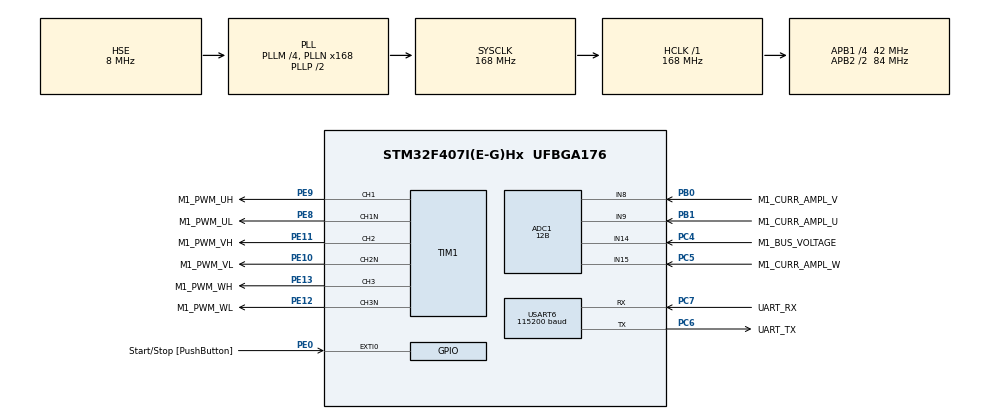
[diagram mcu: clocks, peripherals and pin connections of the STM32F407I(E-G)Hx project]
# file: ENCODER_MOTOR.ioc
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ADC1.Channel-1\#ChannelInjectedConversion=ADC_CHANNEL_9
ADC1.Channel-1\#ChannelRegularConversion=ADC_CHANNEL_14
ADC1.Channel-2\#ChannelInjectedConversion=ADC_CHANNEL_8
ADC1.Channel-3\#ChannelInjectedConversion=ADC_CHANNEL_15
ADC1.ClockPrescaler=ADC_CLOCK_SYNC_PCLK_DIV4
ADC1.ContinuousConvMode=DISABLE
ADC1.DMAContinuousRequests=DISABLE
ADC1.DataAlign=ADC_DATAALIGN_LEFT
ADC1.DiscontinuousConvMode=DISABLE
ADC1.EOCSelection=ADC_EOC_SINGLE_CONV
ADC1.EnableAnalogWatchDog=false
ADC1.EnableInjectedConversion=ENABLE
ADC1.EnableRegularConversion=ENABLE
ADC1.ExternalTrigConv=ADC_SOFTWARE_START
ADC1.ExternalTrigConvEdge=ADC_EXTERNALTRIGCONVEDGE_NONE
ADC1.ExternalTrigInjecConv=ADC_EXTERNALTRIGINJECCONV_T1_CC4
ADC1.ExternalTrigInjecConvEdge=ADC_EXTERNALTRIGINJECCONVEDGE_RISING
ADC1.InjNumberOfConversion=3
ADC1.InjectedConvMode=Discontinuous
ADC1.InjectedOffset-1\#ChannelInjectedConversion=0
ADC1.InjectedOffset-2\#ChannelInjectedConversion=0
ADC1.InjectedOffset-3\#ChannelInjectedConversion=0
ADC1.InjectedRank-1\#ChannelInjectedConversion=1
ADC1.InjectedRank-2\#ChannelInjectedConversion=2
ADC1.InjectedRank-3\#ChannelInjectedConversion=3
ADC1.NbrOfConversion=1
ADC1.NbrOfConversionFlag=1
ADC1.Offset-1\#ChannelRegularConversion=0
ADC1.OffsetNumber-1\#ChannelRegularConversion=ADC_OFFSET_NONE
ADC1.Rank-1\#ChannelRegularConversion=1
ADC1.Resolution=ADC_RESOLUTION_12B
ADC1.SamplingTime-1\#ChannelInjectedConversion=ADC_SAMPLETIME_3CYCLES
ADC1.SamplingTime-1\#ChannelRegularConversion=ADC_SAMPLETIME_56CYCLES
ADC1.SamplingTime-2\#ChannelInjectedConversion=ADC_SAMPLETIME_3CYCLES
ADC1.SamplingTime-3\#ChannelInjectedConversion=ADC_SAMPLETIME_3CYCLES
ADC1.ScanConvMode=ENABLE
ADC1.master=1
ADC2.Channel-1\#ChannelInjectedConversion=ADC_CHANNEL_9
ADC2.Channel-1\#ChannelRegularConversion=ADC_CHANNEL_9
ADC2.Channel-2\#ChannelInjectedConversion=ADC_CHANNEL_8
ADC2.Channel-3\#ChannelInjectedConversion=ADC_CHANNEL_15
ADC2.ClockPrescaler=ADC_CLOCK_SYNC_PCLK_DIV4
ADC2.ContinuousConvMode=DISABLE
ADC2.DMAContinuousRequests=DISABLE
ADC2.DataAlign=ADC_DATAALIGN_LEFT
ADC2.DiscontinuousConvMode=DISABLE
ADC2.EOCSelection=ADC_EOC_SINGLE_CONV
ADC2.EnableAnalogWatchDog=false
ADC2.EnableInjectedConversion=ENABLE
ADC2.EnableRegularConversion=ENABLE
ADC2.ExternalTrigConv=ADC_SOFTWARE_START
ADC2.ExternalTrigConvEdge=ADC_EXTERNALTRIGCONVEDGE_NONE
ADC2.ExternalTrigInjecConv=ADC_EXTERNALTRIGINJECCONV_T1_CC4
ADC2.ExternalTrigInjecConvEdge=ADC_EXTERNALTRIGINJECCONVEDGE_RISING
ADC2.InjNumberOfConversion=3
ADC2.InjectedConvMode=Discontinuous
ADC2.InjectedOffset-1\#ChannelInjectedConversion=0
ADC2.InjectedOffset-2\#ChannelInjectedConversion=0
ADC2.InjectedOffset-3\#ChannelInjectedConversion=0
ADC2.InjectedRank-1\#ChannelInjectedConversion=1
ADC2.InjectedRank-2\#ChannelInjectedConversion=2
ADC2.InjectedRank-3\#ChannelInjectedConversion=3
ADC2.NbrOfConversion=1
ADC2.NbrOfConversionFlag=1
ADC2.Rank-1\#ChannelRegularConversion=1
ADC2.Resolution=ADC_RESOLUTION_12B
ADC2.SamplingTime-1\#ChannelInjectedConversion=ADC_SAMPLETIME_3CYCLES
ADC2.SamplingTime-1\#ChannelRegularConversion=ADC_SAMPLETIME_3CYCLES
ADC2.SamplingTime-2\#ChannelInjectedConversion=ADC_SAMPLETIME_3CYCLES
ADC2.SamplingTime-3\#ChannelInjectedConversion=ADC_SAMPLETIME_3CYCLES
ADC2.ScanConvMode=ENABLE
ExtraMW=MotorControl
ExtraMW.MotorControl.Config=MotorControl
ExtraMW.MotorControl.Mode=MotorControl
ExtraMW.MotorControl.Root=MCSDK_v5.4.8/MotorControl
ExtraMW.MotorControl.Template=templates
Mcu.Family=STM32F4
Mcu.Name=STM32F407I(E-G)Hx
Mcu.Package=UFBGA176
MotorControl.ADC_1_PERIPH=ADC1
MotorControl.ADC_2_PERIPH=ADC2
MotorControl.ADC_AHBPERIPH=RCC_AHBPeriph_ADC12
MotorControl.ADC_CLOCK_WB_DIV=1
MotorControl.ADC_CLOCK_WB_FREQ=21
MotorControl.ADC_PERIPH=ADC1
MotorControl.ADC_REFERENCE_VOLTAGE=3.30
MotorControl.ALIGNMENT_ANGLE_DEG=90
MotorControl.ALIGNMENT_DURATION=700
MotorControl.AMPLIFICATION_GAIN=20.00
MotorControl.ANGC={0,0,0,0,0,0,0,0}
MotorControl.AUXILIARY_SPEED_MEASUREMENT_SELECTION=AUX_STATE_OBSERVER_CORDIC
MotorControl.AUX_STATE_OBSERVER_CORDIC=true
MotorControl.BEMF_CONSISTENCY_GAIN=64
MotorControl.BEMF_CONSISTENCY_TOL=64
MotorControl.BKIN1_FILTER=0
MotorControl.BKIN2_FILTER=0
MotorControl.BKIN2_MODE=NONE
MotorControl.BKIN_MODE=NONE
MotorControl.BOARD=CUSTOM
MotorControl.BRKIN2_GPIO_AF=GPIO_AF_2
MotorControl.BRKIN_GPIO_AF=GPIO_AF_2
MotorControl.BUS_VOLTAGE_READING=true
MotorControl.CCMRAM_ENABLED=false
MotorControl.CLOCK_FREQUENCY=CPU_CLK_168_MHZ
MotorControl.CLOCK_SOURCE=EXTERNAL
MotorControl.CONSTANT1_D=147062
MotorControl.CONSTANT1_Q=147062
MotorControl.CONSTANT2_QD=28666
MotorControl.CORD_BEMF_CONSISTENCY_GAIN=64
MotorControl.CORD_BEMF_CONSISTENCY_TOL=64
MotorControl.CORD_F1=16384
MotorControl.CORD_F2=16384
MotorControl.CORD_FIFO_DEPTH_01HZ=64
MotorControl.CORD_FIFO_DEPTH_DPP=64
MotorControl.CORD_GAIN1=-20932
MotorControl.CORD_GAIN2=20828
MotorControl.CORD_MAX_ACCEL_DPPP=26
MotorControl.CORD_MEAS_ERRORS_BEFORE_FAULTS=50
MotorControl.CORD_VARIANCE_THRESHOLD=4
MotorControl.CPU_CLK_168_MHZ=true
MotorControl.CTRBDID=0
MotorControl.CUBE_MX_VER=6.7.0
MotorControl.CURRENT_READING_TOPOLOGY=THREE_SHUNT_INDEPENDENT_RESOURCES
MotorControl.CURR_SAMPLING_TIME=3
MotorControl.DAC_EMULATED=false
MotorControl.DAC_FUNCTIONALITY=false
MotorControl.DAC_TIMER_CH1_GPIO_PIN=LL_GPIO_PIN_0
MotorControl.DAC_TIMER_CH1_GPIO_PORT=GPIOA
MotorControl.DAC_TIMER_CH2_GPIO_PIN=LL_GPIO_PIN_0
MotorControl.DAC_TIMER_CH2_GPIO_PORT=GPIOA
MotorControl.DAC_TIMER_SELECTION=TIM3
MotorControl.DC_CURRENT_RS_MEAS=13.85
MotorControl.DEBUG_DAC_CH1=false
MotorControl.DEBUG_DAC_CH2=false
MotorControl.DEFAULT_CONTROL_MODE=STC_SPEED_MODE
MotorControl.DEFAULT_DAC_CHANNEL_1=MC_PROTOCOL_REG_I_A
MotorControl.DEFAULT_DAC_CHANNEL_2=MC_PROTOCOL_REG_I_B
MotorControl.DEFAULT_DAC_MOTOR=0
MotorControl.DEFAULT_FLUX_COMPONENT=0
MotorControl.DEFAULT_TARGET_SPEED_RPM=1000
MotorControl.DEFAULT_TORQUE_COMPONENT=0
MotorControl.DISSIPATIVE_BRAKE_POLARITY=DOUT_ACTIVE_HIGH
MotorControl.DRIVES_NUMBER_SELECTION=SINGLEDRIVE
MotorControl.EMERGENCY2_STOP_GPIO_PIN=LL_GPIO_PIN_6
MotorControl.EMERGENCY2_STOP_GPIO_PORT=GPIOA
MotorControl.EMERGENCY_STOP_GPIO_PIN=LL_GPIO_PIN_6
MotorControl.EMERGENCY_STOP_GPIO_PORT=GPIOA
MotorControl.ENABLE_SL_ALGO_FROM_PHASE=1
MotorControl.ENCODER_AVAILABLE=false
MotorControl.ENCODER_PPR=1000
MotorControl.ENC_AVERAGING_FIFO_DEPTH=16
MotorControl.ENC_A_GPIO_PIN=LL_GPIO_PIN_4
MotorControl.ENC_A_GPIO_PORT=GPIOB
MotorControl.ENC_B_GPIO_PIN=LL_GPIO_PIN_5
MotorControl.ENC_B_GPIO_PORT=GPIOB
MotorControl.ENC_ICx_FILTER=64
MotorControl.ENC_INVERT_SPEED=false
MotorControl.ENC_MEAS_ERRORS_BEFORE_FAULTS=50
MotorControl.ENC_TIMER_REMAPPING=NO_REMAP_TIM3
MotorControl.ENC_TIMER_SELECTION=ENC_TIM3
MotorControl.ENC_USE_CH3=false
MotorControl.EXT_CLK_8_MHZ=true
MotorControl.EXT_CLOCK_FREQUENCY=EXT_CLK_8_MHZ
MotorControl.F1=16384
MotorControl.F2=4096
MotorControl.FEEDBACK_NET_FILTERING=false
MotorControl.FEED_FORWARD_CURRENT_REG_ENABLING=false
MotorControl.FINAL_I_ALIGNMENT=2383
MotorControl.FLUX_WEAKENING_ENABLING=false
MotorControl.FW_KIDIV=32768
MotorControl.FW_KI_GAIN=5000
MotorControl.FW_KPDIV=32768
MotorControl.FW_KP_GAIN=3000
MotorControl.FW_VOLTAGE_REF=985
MotorControl.GAIN1=-23932
MotorControl.GAIN2=20828
MotorControl.H1_GPIO_PIN=LL_GPIO_PIN_10
MotorControl.H1_GPIO_PORT=GPIOH
MotorControl.H2_GPIO_PIN=LL_GPIO_PIN_11
MotorControl.H2_GPIO_PORT=GPIOH
MotorControl.H3_GPIO_PIN=LL_GPIO_PIN_12
MotorControl.H3_GPIO_PORT=GPIOH
MotorControl.HALL_AVERAGING_FIFO_DEPTH=6
MotorControl.HALL_ICx_FILTER=96
MotorControl.HALL_MEAS_ERRORS_BEFORE_FAULTS=50
MotorControl.HALL_MTPA=false
MotorControl.HALL_PHASE_SHIFT=120
MotorControl.HALL_SENSORS_AVAILABLE=false
MotorControl.HALL_SENSORS_PLACEMENT=DEGREES_120
MotorControl.HALL_TIMER_REMAPPING=NO_REMAP_TIM5
MotorControl.HALL_TIMER_SELECTION=HALL_TIM5
MotorControl.HFI_AMPLITUDE=25
MotorControl.HFI_DC_0_COEFF=0.00146
MotorControl.HFI_DC_1_COEFF=0.002921
MotorControl.HFI_DC_2_COEFF=0.00146
MotorControl.HFI_DC_3_COEFF=1.889033
MotorControl.HFI_DC_4_COEFF=-0.894874
MotorControl.HFI_DEBUG_MODE=false
MotorControl.HFI_FREQUENCY=400
MotorControl.HFI_HIFRAMPLSCAN=25
MotorControl.HFI_HP_ID_0_COEFF=0.939693
MotorControl.HFI_HP_ID_1_COEFF=-1.879386
MotorControl.HFI_HP_ID_2_COEFF=0.939693
MotorControl.HFI_HP_ID_3_COEFF=1.875746
MotorControl.HFI_HP_ID_4_COEFF=-0.883026
MotorControl.HFI_IDH_DELAY=32400
MotorControl.HFI_LOCKFREQ=33
MotorControl.HFI_LP_ID_0_COEFF=0.00597
MotorControl.HFI_LP_ID_1_COEFF=0.011941
MotorControl.HFI_LP_ID_2_COEFF=0.00597
MotorControl.HFI_LP_ID_3_COEFF=1.769837
MotorControl.HFI_LP_ID_4_COEFF=-0.793719
MotorControl.HFI_MAXANGLEDIFF=3640
MotorControl.HFI_MINIMUM_SPEED_RPM=402
MotorControl.HFI_NOTCH_IQD_0_COEFF=0.969619
MotorControl.HFI_NOTCH_IQD_1_COEFF=-1.923946
MotorControl.HFI_NOTCH_IQD_2_COEFF=0.969619
MotorControl.HFI_NOTCH_IQD_3_COEFF=1.923946
MotorControl.HFI_NOTCH_IQD_4_COEFF=-0.939237
MotorControl.HFI_NSDETPOINTSSKIP=10
MotorControl.HFI_NSMAXDETPOINTS=20
MotorControl.HFI_NS_MIN_SAT_DIFF=0
MotorControl.HFI_PID_KIDIV=32768
MotorControl.HFI_PID_KI_DEFAULT=400
MotorControl.HFI_PID_KPDIV=16384
MotorControl.HFI_PID_KP_DEFAULT=800
MotorControl.HFI_PLL_KI_DEFAULT=0.00400
MotorControl.HFI_PLL_KP_DEFAULT=0.00060
MotorControl.HFI_RESTARTTIMESEC=0.1
MotorControl.HFI_RESTART_RPM_TH=(((HFI_STO_RPM_TH)+(STO_HFI_RPM_TH))/2)
MotorControl.HFI_REVERT_DIRECTION=true
MotorControl.HFI_SCANROTATIONSNO=3
MotorControl.HFI_SPD_BUFFER_DEPTH_01HZ=64
MotorControl.HFI_STEPANGLE=3640
MotorControl.HFI_STO_RPM_TH=OBS_MINIMUM_SPEED_RPM
MotorControl.HFI_WAITAFTERNS2=4
MotorControl.HFI_WAITBEFORESN=6
MotorControl.HFI_WAITSYNCH=20
MotorControl.HFI_WAITTRACK=20
MotorControl.HIGH_SIDE_BRAKE_STATE=false
MotorControl.HIGH_SIDE_IDLE_STATE=false
MotorControl.HW_COMPLEMENTED_LOW_SIDE=false
MotorControl.HW_DEAD_TIME_NS=100
MotorControl.HW_OV_CURRENT_PROT_BYPASS=false
MotorControl.ID_DEMAG=-16502
MotorControl.INRUSH_CURRLIMIT_AT_POWER_ON=true
MotorControl.INRUSH_CURRLIMIT_CHANGE_AFTER_MS=1000
MotorControl.INRUSH_CURRLIMIT_ENABLING=false
MotorControl.INRUSH_CURRLIMIT_GPIO_PIN=LL_GPIO_PIN_4
MotorControl.INRUSH_CURRLIMIT_GPIO_PORT=GPIOE
MotorControl.INRUSH_CURR_LIMITER_POLARITY=DOUT_ACTIVE_HIGH
MotorControl.INTERNAL_OVERCURRENTPROTECTION=false
MotorControl.INTERNAL_OVERVOLTAGEPROTECTION=false
MotorControl.IPs=NVIC,RCC,SYS,MotorControl,ADC1,ADC2,TIM1,USART6
MotorControl.IQMAX=16502
MotorControl.LCD_JOYSTICK_FUNCTIONALITY=false
MotorControl.LCD_MODE=LCD_FULL
MotorControl.LDLQ_RATIO=1.000
MotorControl.LOW_SIDE_BRAKE_STATE=false
MotorControl.LOW_SIDE_IDLE_STATE=false
MotorControl.LOW_SIDE_SIGNALS_ENABLING=LS_PWM_TIMER
MotorControl.LS=0.000200
MotorControl.MAX_APPLICATION_SPEED=5500
MotorControl.MAX_MODULATION_89_PER_CENT=true
MotorControl.MAX_MODULATION_INDEX=MAX_MODULATION_89_PER_CENT
MotorControl.MCU=STM32F407IG
MotorControl.MCU_TYPE=STM32F4xx
MotorControl.MC_WORKBENCH_VERSION=5.4.8.21553
MotorControl.MEAS_ERRORS_BEFORE_FAULTS=50
MotorControl.MIN_APPLICATION_SPEED=0
MotorControl.MOTOR_MAX_SPEED_RPM=5500
MotorControl.MOTOR_TYPE=PMSM
MotorControl.MOTOR_VOLTAGE_CONSTANT=4.4
MotorControl.MTPA_ENABLING=false
MotorControl.NB_CONSECUTIVE_TESTS=1
MotorControl.NOMINAL_BUS_VOLTAGE_V=24
MotorControl.NOMINAL_CURRENT=16502
MotorControl.OBS_MEAS_ERRORS_BEFORE_FAULTS=50
MotorControl.OBS_MINIMUM_SPEED_RPM=700
MotorControl.OCPA_INVERTINGINPUT=COMPX_InvertingInput_VREF
MotorControl.OCPA_INVERTINGINPUT_GPIO_PIN=LL_GPIO_PIN_4
MotorControl.OCPA_INVERTINGINPUT_GPIO_PORT=GPIOA
MotorControl.OCPA_INVERTINGINPUT_MODE=INT_MODE
MotorControl.OCPA_NONINVERTINGINPUT=COMP1_NonInvertingInput_PA1
MotorControl.OCPA_NONINVERTINGINPUT_GPIO_PIN=LL_GPIO_PIN_1
MotorControl.OCPA_NONINVERTINGINPUT_GPIO_PORT=GPIOA
MotorControl.OCPA_OUTPUT=COMP_Output_TIM1BKIN2
MotorControl.OCPA_OUTPUTPOL=COMP_OutputPol_NonInverted
MotorControl.OCPA_OUTPUT_GPIO_AF=GPIO_AF_8
MotorControl.OCPA_OUTPUT_GPIO_PIN=LL_GPIO_PIN_0
MotorControl.OCPA_OUTPUT_GPIO_PORT=GPIOA
MotorControl.OCPA_OUTPUT_MODE=INT_MODE
MotorControl.OCPA_SELECTION=COMP1
MotorControl.OCPB_INVERTINGINPUT=COMPX_InvertingInput_VREF
MotorControl.OCPB_INVERTINGINPUT_GPIO_PIN=LL_GPIO_PIN_4
MotorControl.OCPB_INVERTINGINPUT_GPIO_PORT=GPIOA
MotorControl.OCPB_INVERTINGINPUT_MODE=INT_MODE
MotorControl.OCPB_NONINVERTINGINPUT=COMP2_NonInvertingInput_PA7
MotorControl.OCPB_NONINVERTINGINPUT_GPIO_PIN=LL_GPIO_PIN_7
MotorControl.OCPB_NONINVERTINGINPUT_GPIO_PORT=GPIOA
MotorControl.OCPB_OUTPUT=COMP_Output_TIM1BKIN2
MotorControl.OCPB_OUTPUTPOL=COMP_OutputPol_NonInverted
MotorControl.OCPB_OUTPUT_GPIO_AF=GPIO_AF_8
MotorControl.OCPB_OUTPUT_GPIO_PIN=LL_GPIO_PIN_2
MotorControl.OCPB_OUTPUT_GPIO_PORT=GPIOA
MotorControl.OCPB_OUTPUT_MODE=INT_MODE
MotorControl.OCPB_SELECTION=COMP2
MotorControl.OCPC_INVERTINGINPUT=COMPX_InvertingInput_VREF
MotorControl.OCPC_INVERTINGINPUT_GPIO_PIN=LL_GPIO_PIN_4
MotorControl.OCPC_INVERTINGINPUT_GPIO_PORT=GPIOA
MotorControl.OCPC_INVERTINGINPUT_MODE=INT_MODE
MotorControl.OCPC_NONINVERTINGINPUT=COMP3_NonInvertingInput_PD14
MotorControl.OCPC_NONINVERTINGINPUT_GPIO_PIN=LL_GPIO_PIN_14
MotorControl.OCPC_NONINVERTINGINPUT_GPIO_PORT=GPIOD
MotorControl.OCPC_OUTPUT=COMP_Output_TIM1BKIN2
MotorControl.OCPC_OUTPUTPOL=COMP_OutputPol_NonInverted
MotorControl.OCPC_OUTPUT_GPIO_AF=GPIO_AF_7
MotorControl.OCPC_OUTPUT_GPIO_PIN=LL_GPIO_PIN_8
MotorControl.OCPC_OUTPUT_GPIO_PORT=GPIOC
MotorControl.OCPC_OUTPUT_MODE=INT_MODE
MotorControl.OCPC_SELECTION=COMP3
MotorControl.OCPREF=23830
MotorControl.OCP_COMP_THRESHOLD=0.50
MotorControl.OCP_FILTER=COMP_Mode_HighSpeed
MotorControl.OCP_INVERTINGINPUT=COMPX_InvertingInput_VREF
MotorControl.OCP_INVERTINGINPUT_GPIO_PIN=LL_GPIO_PIN_4
MotorControl.OCP_INVERTINGINPUT_GPIO_PORT=GPIOA
MotorControl.OCP_INVERTINGINPUT_MODE=INT_MODE
MotorControl.OCP_NONINVERTINGINPUT=COMP2_NonInvertingInput_PA7
MotorControl.OCP_NONINVERTINGINPUT_GPIO_PIN=LL_GPIO_PIN_7
MotorControl.OCP_NONINVERTINGINPUT_GPIO_PORT=GPIOA
MotorControl.OCP_OUTPUT=COMP_Output_TIM1BKIN2
MotorControl.OCP_OUTPUTPOL=COMP_OutputPol_NonInverted
MotorControl.OCP_OUTPUT_GPIO_AF=GPIO_AF_8
MotorControl.OCP_OUTPUT_GPIO_PIN=LL_GPIO_PIN_2
MotorControl.OCP_OUTPUT_GPIO_PORT=GPIOA
MotorControl.OCP_OUTPUT_MODE=INT_MODE
MotorControl.OCP_SELECTION=COMP2
MotorControl.OFST={0,0,0,0,0,0,0,0}
MotorControl.ON_OVER_VOLTAGE=TURN_OFF_PWM
MotorControl.OPAMP1_INVERTINGINPUT=OPAMP1_InvertingInput_PGA
MotorControl.OPAMP1_INVERTINGINPUT_GPIO_PIN=LL_GPIO_PIN_3
MotorControl.OPAMP1_INVERTINGINPUT_GPIO_PORT=GPIOA
MotorControl.OPAMP1_INVERTINGINPUT_MODE=INT_MODE
MotorControl.OPAMP1_NONINVERTINGINPUT_PHA=OPAMP1_NonInvertingInput_PA1
MotorControl.OPAMP1_NONINVERTINGINPUT_PHA_GPIO_PIN=LL_GPIO_PIN_1
MotorControl.OPAMP1_NONINVERTINGINPUT_PHA_GPIO_PORT=GPIOA
MotorControl.OPAMP1_NONINVERTINGINPUT_PHB=OPAMP1_NonInvertingInput_PA7
MotorControl.OPAMP1_NONINVERTINGINPUT_PHB_GPIO_PIN=LL_GPIO_PIN_7
MotorControl.OPAMP1_NONINVERTINGINPUT_PHB_GPIO_PORT=GPIOA
MotorControl.OPAMP1_OUT_GPIO_PIN=LL_GPIO_PIN_2
MotorControl.OPAMP1_OUT_GPIO_PORT=GPIOA
MotorControl.OPAMP1_SELECTION=OPAMP1
MotorControl.OPAMP2_INVERTINGINPUT=OPAMP2_InvertingInput_PGA
MotorControl.OPAMP2_INVERTINGINPUT_GPIO_PIN=LL_GPIO_PIN_5
MotorControl.OPAMP2_INVERTINGINPUT_GPIO_PORT=GPIOC
MotorControl.OPAMP2_INVERTINGINPUT_MODE=INT_MODE
MotorControl.OPAMP2_NONINVERTINGINPUT_PHA=OPAMP2_NonInvertingInput_PB14
MotorControl.OPAMP2_NONINVERTINGINPUT_PHA_GPIO_PIN=LL_GPIO_PIN_14
MotorControl.OPAMP2_NONINVERTINGINPUT_PHA_GPIO_PORT=GPIOB
MotorControl.OPAMP2_NONINVERTINGINPUT_PHB=OPAMP2_NonInvertingInput_PA7
MotorControl.OPAMP2_NONINVERTINGINPUT_PHB_GPIO_PIN=LL_GPIO_PIN_7
MotorControl.OPAMP2_NONINVERTINGINPUT_PHB_GPIO_PORT=GPIOA
MotorControl.OPAMP2_NONINVERTINGINPUT_PHC=OPAMP2_NonInvertingInput_PB14
MotorControl.OPAMP2_NONINVERTINGINPUT_PHC_GPIO_PIN=LL_GPIO_PIN_14
MotorControl.OPAMP2_NONINVERTINGINPUT_PHC_GPIO_PORT=GPIOB
MotorControl.OPAMP2_OUT_GPIO_PIN=LL_GPIO_PIN_6
MotorControl.OPAMP2_OUT_GPIO_PORT=GPIOA
MotorControl.OPAMP2_SELECTION=OPAMP2
MotorControl.OPAMP3_INVERTINGINPUT=OPAMP1_InvertingInput_PGA
MotorControl.OPAMP3_INVERTINGINPUT_GPIO_PIN=LL_GPIO_PIN_0
MotorControl.OPAMP3_INVERTINGINPUT_GPIO_PORT=GPIOA
MotorControl.OPAMP3_INVERTINGINPUT_MODE=INT_MODE
MotorControl.OPAMP3_SELECTION=OPAMP1
MotorControl.OPAMP_INVERTINGINPUT=OPAMP1_InvertingInput_PGA
MotorControl.OPAMP_INVERTINGINPUT_GPIO_PIN=LL_GPIO_PIN_3
MotorControl.OPAMP_INVERTINGINPUT_GPIO_PORT=GPIOA
MotorControl.OPAMP_INVERTINGINPUT_MODE=INT_MODE
MotorControl.OPAMP_NONINVERTINGINPUT=OPAMP1_NonInvertingInput_PA7
MotorControl.OPAMP_NONINVERTINGINPUT_GPIO_PIN=LL_GPIO_PIN_7
MotorControl.OPAMP_NONINVERTINGINPUT_GPIO_PORT=GPIOA
MotorControl.OPAMP_OUT_GPIO_PIN=LL_GPIO_PIN_2
MotorControl.OPAMP_OUT_GPIO_PORT=GPIOA
MotorControl.OPAMP_PGACONNECT=OPAMP_PGAConnect_No
MotorControl.OPAMP_PGAGAIN=OPAMP_OPAMP_PGAGain_2
MotorControl.OPAMP_SELECTION=OPAMP1
MotorControl.OPAMP_TYPE_GAIN=INTERNAL
MotorControl.OPEN_LOOP_FOC=false
MotorControl.OPEN_LOOP_K=44
MotorControl.OPEN_LOOP_OFF=4400
MotorControl.OPEN_LOOP_SPEED_RAMP_DURATION_MS=1000
MotorControl.OPEN_LOOP_SPEED_RPM=100
MotorControl.OPEN_LOOP_VF=false
MotorControl.OPEN_LOOP_VOLTAGE_d=6000
MotorControl.OVERCURR_FEEDBACK_POLARITY=EMSTOP_ACTIVE_LOW
MotorControl.OVERCURR_PROTECTION_HW_DISABLING=DOUT_ACTIVE_HIGH
MotorControl.OVPREF=23830
MotorControl.OVP_FILTER=COMP_Mode_HighSpeed
MotorControl.OVP_INVERTINGINPUT=COMPX_InvertingInput_VREF
MotorControl.OVP_INVERTINGINPUT_GPIO_PIN=LL_GPIO_PIN_4
MotorControl.OVP_INVERTINGINPUT_GPIO_PORT=GPIOA
MotorControl.OVP_INVERTINGINPUT_MODE=INT_MODE
MotorControl.OVP_NONINVERTINGINPUT=COMP7_NonInvertingInput_PA0
MotorControl.OVP_NONINVERTINGINPUT_GPIO_PIN=LL_GPIO_PIN_0
MotorControl.OVP_NONINVERTINGINPUT_GPIO_PORT=GPIOA
MotorControl.OVP_OUTPUT=COMP_Output_TIM1BKIN
MotorControl.OVP_OUTPUTPOL=COMP_OutputPol_NonInverted
MotorControl.OVP_OUTPUT_GPIO_AF=GPIO_AF_3
MotorControl.OVP_OUTPUT_GPIO_PIN=LL_GPIO_PIN_2
MotorControl.OVP_OUTPUT_GPIO_PORT=GPIOC
MotorControl.OVP_OUTPUT_MODE=INT_MODE
MotorControl.OVP_SELECTION=COMP7
MotorControl.OV_CURR_BYPASS_GPIO_PIN=LL_GPIO_PIN_5
MotorControl.OV_CURR_BYPASS_GPIO_PORT=GPIOE
MotorControl.OV_TEMPERATURE_HYSTERESIS_C=10
MotorControl.OV_TEMPERATURE_PROT_ENABLING=false
MotorControl.OV_TEMPERATURE_THRESHOLD_C=70
MotorControl.OV_VOLTAGE_PROT_ENABLING=false
MotorControl.OV_VOLTAGE_THRESHOLD_V=40
MotorControl.PHASE1_DURATION=300
MotorControl.PHASE1_FINAL_CURRENT=595
MotorControl.PHASE1_FINAL_SPEED_RPM=50
MotorControl.PHASE2_DURATION=300
MotorControl.PHASE2_FINAL_CURRENT=834
MotorControl.PHASE2_FINAL_SPEED_RPM=100
MotorControl.PHASE3_DURATION=500
MotorControl.PHASE3_FINAL_CURRENT=1072
MotorControl.PHASE3_FINAL_SPEED_RPM=300
MotorControl.PHASE4_DURATION=600
MotorControl.PHASE4_FINAL_CURRENT=1191
MotorControl.PHASE4_FINAL_SPEED_RPM=500
MotorControl.PHASE5_DURATION=800
MotorControl.PHASE5_FINAL_CURRENT=1191
MotorControl.PHASE5_FINAL_SPEED_RPM=1000
MotorControl.PHASE_CURRENTS_ADC=ADC1_2
MotorControl.PHASE_CURRENTS_CHANNEL=ADC_CHANNEL_9
MotorControl.PHASE_CURRENTS_GPIO_PIN=LL_GPIO_PIN_1
MotorControl.PHASE_CURRENTS_GPIO_PORT=GPIOB
MotorControl.PHASE_UH_GPIO_AF=GPIO_AF_2
MotorControl.PHASE_UH_GPIO_PIN=LL_GPIO_PIN_9
MotorControl.PHASE_UH_GPIO_PORT=GPIOE
MotorControl.PHASE_UH_POLARITY=H_ACTIVE_HIGH
MotorControl.PHASE_UL_GPIO_AF=GPIO_AF_2
MotorControl.PHASE_UL_GPIO_PIN=LL_GPIO_PIN_8
MotorControl.PHASE_UL_GPIO_PORT=GPIOE
MotorControl.PHASE_UL_POLARITY=L_ACTIVE_HIGH
MotorControl.PHASE_U_CURR_ADC=ADC1_2
MotorControl.PHASE_U_CURR_CHANNEL=ADC_CHANNEL_9
MotorControl.PHASE_U_GPIO_PIN=LL_GPIO_PIN_1
MotorControl.PHASE_U_GPIO_PORT=GPIOB
MotorControl.PHASE_VH_GPIO_AF=GPIO_AF_2
MotorControl.PHASE_VH_GPIO_PIN=LL_GPIO_PIN_11
MotorControl.PHASE_VH_GPIO_PORT=GPIOE
MotorControl.PHASE_VH_POLARITY=H_ACTIVE_HIGH
MotorControl.PHASE_VL_GPIO_AF=GPIO_AF_2
MotorControl.PHASE_VL_GPIO_PIN=LL_GPIO_PIN_10
MotorControl.PHASE_VL_GPIO_PORT=GPIOE
MotorControl.PHASE_VL_POLARITY=L_ACTIVE_HIGH
MotorControl.PHASE_V_CURR_ADC=ADC1_2
MotorControl.PHASE_V_CURR_CHANNEL=ADC_CHANNEL_8
MotorControl.PHASE_V_GPIO_PIN=LL_GPIO_PIN_0
MotorControl.PHASE_V_GPIO_PORT=GPIOB
MotorControl.PHASE_WH_GPIO_AF=GPIO_AF_2
MotorControl.PHASE_WH_GPIO_PIN=LL_GPIO_PIN_13
MotorControl.PHASE_WH_GPIO_PORT=GPIOE
MotorControl.PHASE_WH_POLARITY=H_ACTIVE_HIGH
MotorControl.PHASE_WL_GPIO_AF=GPIO_AF_2
MotorControl.PHASE_WL_GPIO_PIN=LL_GPIO_PIN_12
MotorControl.PHASE_WL_GPIO_PORT=GPIOE
MotorControl.PHASE_WL_POLARITY=L_ACTIVE_HIGH
MotorControl.PHASE_W_CURR_ADC=ADC1_2
MotorControl.PHASE_W_CURR_CHANNEL=ADC_CHANNEL_15
MotorControl.PHASE_W_GPIO_PIN=LL_GPIO_PIN_5
MotorControl.PHASE_W_GPIO_PORT=GPIOC
MotorControl.PID_FLUX_KD_DEFAULT=100
MotorControl.PID_FLUX_KI_DEFAULT=3117
MotorControl.PID_FLUX_KP_DEFAULT=1000
MotorControl.PID_SPEED_KD_DEFAULT=0
MotorControl.PID_SPEED_KI_DEFAULT=50
MotorControl.PID_SPEED_KP_DEFAULT=100
MotorControl.PID_TORQUE_KD_DEFAULT=100
MotorControl.PID_TORQUE_KI_DEFAULT=3117
MotorControl.PID_TORQUE_KP_DEFAULT=1000
MotorControl.PLL_KI_GAIN=8
MotorControl.PLL_KP_GAIN=269
MotorControl.POLE_PAIR_NUM=4
MotorControl.POSITION_CTRL_ENABLING=false
MotorControl.PWBDID=0
MotorControl.PWM_FREQUENCY=20000
MotorControl.PWM_TIMER_REMAPPING=PWM_NO_REMAP
MotorControl.PWM_TIMER_SELECTION=PWM_TIM1
MotorControl.REGCONVADC=ADC1
MotorControl.REGULATION_EXECUTION_RATE=1
MotorControl.RS=0.12
MotorControl.RSHUNT=0.00300
MotorControl.RTOS=NONE
MotorControl.R_BRAKE_GPIO_PIN=LL_GPIO_PIN_5
MotorControl.R_BRAKE_GPIO_PORT=GPIOE
MotorControl.R_BRAKE_SWITCH_OFF_THRES_V=32
MotorControl.SEGDIV=0
MotorControl.SERIAL_COMMUNICATION=true
MotorControl.SERIAL_COM_CHANNEL1=MC_PROTOCOL_REG_I_A
MotorControl.SERIAL_COM_CHANNEL2=MC_PROTOCOL_REG_I_A
MotorControl.SERIAL_COM_MODE=COM_BIDIRECTIONAL
MotorControl.SERIAL_COM_MOTOR=0
MotorControl.SHARED_SIGNAL_ENABLE=false
MotorControl.SINGLEDRIVE=true
MotorControl.SPD_DIFFERENTIAL_TERM_ENABLING=false
MotorControl.SPEED_BAND_LOWER_LIMIT=15
MotorControl.SPEED_BAND_UPPER_LIMIT=17
MotorControl.SPEED_FEEDBACK_CHECK=true
MotorControl.SPEED_LOOP_FREQUENCY_HZ=100
MotorControl.SPEED_SENSOR_SELECTION=STATE_OBSERVER_PLL
MotorControl.SP_KDDIV=16
MotorControl.SP_KIDIV=256
MotorControl.SP_KPDIV=16
MotorControl.STARTING_ANGLE_DEG=90
MotorControl.START_STOP_BTN=true
MotorControl.START_STOP_GPIO_PIN=LL_GPIO_PIN_0
MotorControl.START_STOP_GPIO_PORT=GPIOE
MotorControl.START_STOP_POLARITY=DIN_ACTIVE_LOW
MotorControl.START_STOP_POLARITY_EDGE=GPIO_PULLUP
MotorControl.STATE_OBSERVER_PLL=true
MotorControl.STM32F4xx=true
MotorControl.STO_FIFO_DEPTH_01HZ=64
MotorControl.STO_FIFO_DEPTH_DPP=64
MotorControl.STO_HFI_RPM_TH=460
MotorControl.SW_DEADTIME_NS=1000
MotorControl.SW_OV_CURRENT_PROT_ENABLING=false
MotorControl.T0_C=25
MotorControl.TEMPERATURE_READING=false
MotorControl.TEMP_ADC_SAMPLING_TIME=28
MotorControl.TEMP_FDBK_ADC=ADC1
MotorControl.TEMP_FDBK_CHANNEL=ADC_CHANNEL_13
MotorControl.TEMP_FDBK_GPIO_PIN=LL_GPIO_PIN_3
MotorControl.TEMP_FDBK_GPIO_PORT=GPIOC
MotorControl.TFDIFFERENTIAL_TERM_ENABLING=false
MotorControl.TF_KDDIV=8192
MotorControl.TF_KIDIV=16384
MotorControl.TF_KPDIV=1024
MotorControl.THREE_SHUNT_INDEPENDENT_RESOURCES=true
MotorControl.TNOISE_NS=2550
MotorControl.TRANSITION_DURATION=25
MotorControl.TRISE_NS=2550
MotorControl.T_MAX=70
MotorControl.UD_VOLTAGE_THRESHOLD_V=10
MotorControl.USART_REMAPPING=NO_REMAP_USART6
MotorControl.USART_RX_GPIO_PIN=LL_GPIO_PIN_7
MotorControl.USART_RX_GPIO_PORT=GPIOC
MotorControl.USART_SELECTION=USE_USART6
MotorControl.USART_SPEED=115200
MotorControl.USART_TX_GPIO_PIN=LL_GPIO_PIN_6
MotorControl.USART_TX_GPIO_PORT=GPIOC
MotorControl.USE_3OPAMPS=false
MotorControl.USE_INTERNAL_OPAMP=false
MotorControl.UV_VOLTAGE_PROT_ENABLING=false
MotorControl.V0_V=0.926
MotorControl.VARIANCE_THRESHOLD=0.6
MotorControl.VBUS_ADC=ADC1
MotorControl.VBUS_ADC_SAMPLING_TIME=56
MotorControl.VBUS_CHANNEL=ADC_CHANNEL_14
MotorControl.VBUS_GPIO_PIN=LL_GPIO_PIN_4
MotorControl.VBUS_GPIO_PORT=GPIOC
MotorControl.VBUS_PARTITIONING_FACTOR=0.0429
MotorControl.WB_to_Mx_template_version=21-11-15
MotorControl.WB_to_Mx_version=1.5.1
MotorControl.dV_dT=0.025
NVIC.ADC_IRQn=true\:2\:0\:true\:true\:false\:1\:false\:true\:true
NVIC.EXTI0_IRQn=true\:3\:0\:false\:true\:false\:5\:true\:true\:true
NVIC.PriorityGroup=NVIC_PRIORITYGROUP_3
NVIC.TIM1_BRK_TIM9_IRQn=true\:4\:1\:false\:true\:false\:3\:true\:true\:true
NVIC.TIM1_UP_TIM10_IRQn=true\:0\:0\:false\:true\:false\:2\:true\:true\:true
NVIC.USART6_IRQn=true\:3\:1\:true\:true\:false\:4\:true\:true\:true
PB0.GPIO_Label=M1_CURR_AMPL_V
PB0.Signal=SharedAnalog_PB0
PB1.GPIO_Label=M1_CURR_AMPL_U
PB1.Signal=SharedAnalog_PB1
PC4.GPIO_Label=M1_BUS_VOLTAGE
PC4.Signal=ADCx_IN14
PC5.GPIO_Label=M1_CURR_AMPL_W
PC5.Signal=SharedAnalog_PC5
PC6.GPIO_Label=UART_TX
PC6.GPIO_Mode=GPIO_MODE_AF_PP
PC6.GPIO_PuPd=GPIO_NOPULL
PC6.GPIO_Speed=GPIO_SPEED_FREQ_LOW
PC6.Mode=Asynchronous
PC6.Signal=USART6_TX
PC7.GPIO_Label=UART_RX
PC7.GPIO_Mode=GPIO_MODE_AF_PP
PC7.GPIO_PuPd=GPIO_NOPULL
PC7.GPIO_Speed=GPIO_SPEED_FREQ_LOW
PC7.Mode=Asynchronous
PC7.Signal=USART6_RX
PE0.GPIO_Label=Start/Stop [PushButton]
PE0.GPIO_ModeDefaultEXTI=GPIO_MODE_IT_FALLING
PE0.GPIO_PuPd=GPIO_PULLUP
PE0.Signal=GPXTI0
PE10.GPIO_Label=M1_PWM_VL
PE10.GPIO_PuPd=GPIO_PULLDOWN
PE10.GPIO_Speed=GPIO_SPEED_FREQ_HIGH
PE10.Mode=PWM Generation2 CH2 CH2N
PE10.Signal=TIM1_CH2N
PE11.GPIO_Label=M1_PWM_VH
PE11.GPIO_PuPd=GPIO_PULLDOWN
PE11.GPIO_Speed=GPIO_SPEED_FREQ_HIGH
PE11.Signal=S_TIM1_CH2
PE12.GPIO_Label=M1_PWM_WL
PE12.GPIO_PuPd=GPIO_PULLDOWN
PE12.GPIO_Speed=GPIO_SPEED_FREQ_HIGH
PE12.Mode=PWM Generation3 CH3 CH3N
PE12.Signal=TIM1_CH3N
PE13.GPIO_Label=M1_PWM_WH
PE13.GPIO_PuPd=GPIO_PULLDOWN
PE13.GPIO_Speed=GPIO_SPEED_FREQ_HIGH
PE13.Signal=S_TIM1_CH3
PE8.GPIO_Label=M1_PWM_UL
PE8.GPIO_PuPd=GPIO_PULLDOWN
PE8.GPIO_Speed=GPIO_SPEED_FREQ_HIGH
PE8.Mode=PWM Generation1 CH1 CH1N
PE8.Signal=TIM1_CH1N
PE9.GPIO_Label=M1_PWM_UH
PE9.GPIO_PuPd=GPIO_PULLDOWN
PE9.GPIO_Speed=GPIO_SPEED_FREQ_HIGH
PE9.Signal=S_TIM1_CH1
PH0-OSC_IN.Mode=HSE-External-Oscillator
PH0-OSC_IN.Signal=RCC_OSC_IN
PH1-OSC_OUT.Mode=HSE-External-Oscillator
PH1-OSC_OUT.Signal=RCC_OSC_OUT
ProjectManager.HeapSize=0x200
ProjectManager.StackSize=0x400
ProjectManager.TargetToolchain=MDK-ARM V5
RCC.48MHZClocksFreq_Value=84000000
RCC.AHBFreq_Value=168000000
RCC.APB1CLKDivider=RCC_HCLK_DIV4
RCC.APB1Freq_Value=42000000
RCC.APB1TimFreq_Value=84000000
RCC.APB2CLKDivider=RCC_HCLK_DIV2
RCC.APB2Freq_Value=84000000
RCC.APB2TimFreq_Value=168000000
RCC.CortexFreq_Value=168000000
RCC.EnbaleCSS=true
RCC.HCLKFreq_Value=168000000
RCC.HSE_VALUE=8000000
RCC.HSI_VALUE=16000000
RCC.LSE_VALUE=32768
RCC.PLLM=4
RCC.PLLN=168
RCC.PLLSourceVirtual=RCC_PLLSOURCE_HSE
RCC.SYSCLKFreq_VALUE=168000000
RCC.SYSCLKSource=RCC_SYSCLKSOURCE_PLLCLK
RCC.VCOOutputFreq_Value=336000000
SH.ADCx_IN14.0=ADC1_IN14,IN14
SH.S_TIM1_CH1.0=TIM1_CH1,PWM Generation1 CH1 CH1N
SH.S_TIM1_CH2.0=TIM1_CH2,PWM Generation2 CH2 CH2N
SH.S_TIM1_CH3.0=TIM1_CH3,PWM Generation3 CH3 CH3N
SH.SharedAnalog_PB0.0=ADC1_IN8,IN8
SH.SharedAnalog_PB0.1=ADC2_IN8,IN8
SH.SharedAnalog_PB1.0=ADC1_IN9,IN9
SH.SharedAnalog_PB1.1=ADC2_IN9,IN9
SH.SharedAnalog_PC5.0=ADC1_IN15,IN15
SH.SharedAnalog_PC5.1=ADC2_IN15,IN15
TIM1.BreakPolarity=TIM_BREAKPOLARITY_LOW
TIM1.BreakState=TIM_BREAK_DISABLE
TIM1.Channel-PWM\ Generation1\ CH1\ CH1N=TIM_CHANNEL_1
TIM1.Channel-PWM\ Generation2\ CH2\ CH2N=TIM_CHANNEL_2
TIM1.Channel-PWM\ Generation3\ CH3\ CH3N=TIM_CHANNEL_3
TIM1.Channel-PWM\ Generation4\ No\ Output=TIM_CHANNEL_4
TIM1.ClockDivision=TIM_CLOCKDIVISION_DIV2
TIM1.CounterMode=TIM_COUNTERMODE_CENTERALIGNED1
TIM1.DeadTime=((DEAD_TIME_COUNTS) / 2)
TIM1.LockLevel=TIM_LOCKLEVEL_1
TIM1.OCIdleState_1=TIM_OCIDLESTATE_RESET
TIM1.OCIdleState_2=TIM_OCIDLESTATE_RESET
TIM1.OCIdleState_3=TIM_OCIDLESTATE_RESET
TIM1.OCMode_PWM-PWM\ Generation4\ No\ Output=TIM_OCMODE_PWM2
TIM1.OCNIdleState_1=TIM_OCNIDLESTATE_RESET
TIM1.OCNIdleState_2=TIM_OCNIDLESTATE_RESET
TIM1.OCNIdleState_3=TIM_OCNIDLESTATE_RESET
TIM1.OCNPolarity_1=TIM_OCNPOLARITY_HIGH
TIM1.OCNPolarity_2=TIM_OCNPOLARITY_HIGH
TIM1.OCNPolarity_3=TIM_OCNPOLARITY_HIGH
TIM1.OCPolarity_1=TIM_OCPOLARITY_HIGH
TIM1.OCPolarity_2=TIM_OCPOLARITY_HIGH
TIM1.OCPolarity_3=TIM_OCPOLARITY_HIGH
TIM1.OffStateIDLEMode=TIM_OSSI_ENABLE
TIM1.OffStateRunMode=TIM_OSSR_ENABLE
TIM1.Period=((PWM_PERIOD_CYCLES) / 2)
TIM1.Prescaler=((TIM_CLOCK_DIVIDER) - 1)
TIM1.Pulse-PWM\ Generation1\ CH1=((PWM_PERIOD_CYCLES) / 4)
TIM1.Pulse-PWM\ Generation2\ CH2=((PWM_PERIOD_CYCLES) / 4)
TIM1.Pulse-PWM\ Generation3\ CH3=((PWM_PERIOD_CYCLES) / 4)
TIM1.Pulse-PWM\ Generation4\ No\ Output=(((PWM_PERIOD_CYCLES) / 2) - (HTMIN))
TIM1.RepetitionCounter=(REP_COUNTER)
TIM1.TIM_MasterOutputTrigger=TIM_TRGO_RESET
USART6.BaudRate=115200
USART6.VirtualMode=VM_ASYNC
USART6.VirtualMode-Asynchronous=VM_ASYNC
USART6.WordLength=WORDLENGTH_8B
VP_MotorControl_MC_ENABLED.Mode=Enabled
VP_TIM1_VS_ClockSourceITR.Mode=TriggerSource_ITR1
VP_TIM1_VS_ControllerModeTrigger.Mode=Trigger Mode
VP_TIM1_VS_no_output4.Mode=PWM Generation4 No Output
board=custom

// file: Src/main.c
/* USER CODE BEGIN Header */
/**
  ******************************************************************************
  * @file           : main.c
  * @brief          : Main program body
  ******************************************************************************
  * @attention
  *
  * <h2><center>&copy; Copyright (c) 2022 STMicroelectronics.
  * All rights reserved.</center></h2>
  *
  * This software component is licensed by ST under Ultimate Liberty license
  * SLA0044, the "License"; You may not use this file except in compliance with
  * the License. You may obtain a copy of the License at:
  *                             www.st.com/SLA0044
  *
  ******************************************************************************
  */
/* USER CODE END Header */
#include "main.h"

ADC_HandleTypeDef hadc1;
ADC_HandleTypeDef hadc2;

TIM_HandleTypeDef htim1;

UART_HandleTypeDef huart6;

void SystemClock_Config(void);
static void MX_GPIO_Init(void);
static void MX_ADC1_Init(void);
static void MX_ADC2_Init(void);
static void MX_TIM1_Init(void);
static void MX_USART6_UART_Init(void);
static void MX_NVIC_Init(void);

/* USER CODE BEGIN 0 */
uint16_t uFStartStop = 0;
/* USER CODE END 0 */

int main(void)
{

  /* MCU Configuration--------------------------------------------------------*/

  /* Reset of all peripherals, Initializes the Flash interface and the Systick. */
  HAL_Init();

  /* Configure the system clock */
  SystemClock_Config();

  /* Initialize all configured peripherals */
  MX_GPIO_Init();
  MX_ADC1_Init();
  MX_ADC2_Init();
  MX_TIM1_Init();
  MX_USART6_UART_Init();
  MX_MotorControl_Init();

  /* Initialize interrupts */
  MX_NVIC_Init();

  /* Infinite loop */
  while (1)
  {

    /* USER CODE BEGIN 3 */
		if (uFStartStop == 1)
		{
			UI_HandleStartStopButton_cb();
			uFStartStop = 0;
		}
  }
  /* USER CODE END 3 */
}

void SystemClock_Config(void)
{
  RCC_OscInitTypeDef RCC_OscInitStruct = {0};
  RCC_ClkInitTypeDef RCC_ClkInitStruct = {0};

  /** Configure the main internal regulator output voltage
  */
  __HAL_RCC_PWR_CLK_ENABLE();
  __HAL_PWR_VOLTAGESCALING_CONFIG(PWR_REGULATOR_VOLTAGE_SCALE1);

  /** Initializes the RCC Oscillators according to the specified parameters
  * in the RCC_OscInitTypeDef structure.
  */
  RCC_OscInitStruct.OscillatorType = RCC_OSCILLATORTYPE_HSE;
  RCC_OscInitStruct.HSEState = RCC_HSE_ON;
  RCC_OscInitStruct.PLL.PLLState = RCC_PLL_ON;
  RCC_OscInitStruct.PLL.PLLSource = RCC_PLLSOURCE_HSE;
  RCC_OscInitStruct.PLL.PLLM = 4;
  RCC_OscInitStruct.PLL.PLLN = 168;
  RCC_OscInitStruct.PLL.PLLP = RCC_PLLP_DIV2;
  RCC_OscInitStruct.PLL.PLLQ = 4;
  if (HAL_RCC_OscConfig(&RCC_OscInitStruct) != HAL_OK)
  {
    Error_Handler();
  }

  /** Initializes the CPU, AHB and APB buses clocks
  */
  RCC_ClkInitStruct.ClockType = RCC_CLOCKTYPE_HCLK|RCC_CLOCKTYPE_SYSCLK
                              |RCC_CLOCKTYPE_PCLK1|RCC_CLOCKTYPE_PCLK2;
  RCC_ClkInitStruct.SYSCLKSource = RCC_SYSCLKSOURCE_PLLCLK;
  RCC_ClkInitStruct.AHBCLKDivider = RCC_SYSCLK_DIV1;
  RCC_ClkInitStruct.APB1CLKDivider = RCC_HCLK_DIV4;
  RCC_ClkInitStruct.APB2CLKDivider = RCC_HCLK_DIV2;

  if (HAL_RCC_ClockConfig(&RCC_ClkInitStruct, FLASH_LATENCY_5) != HAL_OK)
  {
    Error_Handler();
  }

  /** Enables the Clock Security System
  */
  HAL_RCC_EnableCSS();
}

/**
  * @brief NVIC Configuration.
  * @retval None
  */
static void MX_NVIC_Init(void)
{
  /* ADC_IRQn interrupt configuration */
  HAL_NVIC_SetPriority(ADC_IRQn, 2, 0);
  HAL_NVIC_EnableIRQ(ADC_IRQn);
  /* TIM1_UP_TIM10_IRQn interrupt configuration */
  HAL_NVIC_SetPriority(TIM1_UP_TIM10_IRQn, 0, 0);
  HAL_NVIC_EnableIRQ(TIM1_UP_TIM10_IRQn);
  /* TIM1_BRK_TIM9_IRQn interrupt configuration */
  HAL_NVIC_SetPriority(TIM1_BRK_TIM9_IRQn, 4, 1);
  HAL_NVIC_EnableIRQ(TIM1_BRK_TIM9_IRQn);
  /* USART6_IRQn interrupt configuration */
  HAL_NVIC_SetPriority(USART6_IRQn, 3, 1);
  HAL_NVIC_EnableIRQ(USART6_IRQn);
  /* EXTI0_IRQn interrupt configuration */
  HAL_NVIC_SetPriority(EXTI0_IRQn, 3, 0);
  HAL_NVIC_EnableIRQ(EXTI0_IRQn);
}

static void MX_ADC1_Init(void)
{

  ADC_InjectionConfTypeDef sConfigInjected = {0};
  ADC_ChannelConfTypeDef sConfig = {0};

  /** Configure the global features of the ADC (Clock, Resolution, Data Alignment and number of conversion)
  */
  hadc1.Instance = ADC1;
  hadc1.Init.ClockPrescaler = ADC_CLOCK_SYNC_PCLK_DIV4;
  hadc1.Init.Resolution = ADC_RESOLUTION_12B;
  hadc1.Init.ScanConvMode = ENABLE;
  hadc1.Init.ContinuousConvMode = DISABLE;
  hadc1.Init.DiscontinuousConvMode = DISABLE;
  hadc1.Init.ExternalTrigConvEdge = ADC_EXTERNALTRIGCONVEDGE_NONE;
  hadc1.Init.ExternalTrigConv = ADC_SOFTWARE_START;
  hadc1.Init.DataAlign = ADC_DATAALIGN_LEFT;
  hadc1.Init.NbrOfConversion = 1;
  hadc1.Init.DMAContinuousRequests = DISABLE;
  hadc1.Init.EOCSelection = ADC_EOC_SINGLE_CONV;
  if (HAL_ADC_Init(&hadc1) != HAL_OK)
  {
    Error_Handler();
  }

  /** Configures for the selected ADC injected channel its corresponding rank in the sequencer and its sample time
  */
  sConfigInjected.InjectedChannel = ADC_CHANNEL_9;
  sConfigInjected.InjectedRank = 1;
  sConfigInjected.InjectedNbrOfConversion = 3;
  sConfigInjected.InjectedSamplingTime = ADC_SAMPLETIME_3CYCLES;
  sConfigInjected.ExternalTrigInjecConvEdge = ADC_EXTERNALTRIGINJECCONVEDGE_RISING;
  sConfigInjected.ExternalTrigInjecConv = ADC_EXTERNALTRIGINJECCONV_T1_CC4;
  sConfigInjected.AutoInjectedConv = DISABLE;
  sConfigInjected.InjectedDiscontinuousConvMode = ENABLE;
  sConfigInjected.InjectedOffset = 0;
  if (HAL_ADCEx_InjectedConfigChannel(&hadc1, &sConfigInjected) != HAL_OK)
  {
    Error_Handler();
  }

  /** Configures for the selected ADC injected channel its corresponding rank in the sequencer and its sample time
  */
  sConfigInjected.InjectedChannel = ADC_CHANNEL_8;
  sConfigInjected.InjectedRank = 2;
  if (HAL_ADCEx_InjectedConfigChannel(&hadc1, &sConfigInjected) != HAL_OK)
  {
    Error_Handler();
  }

  /** Configures for the selected ADC injected channel its corresponding rank in the sequencer and its sample time
  */
  sConfigInjected.InjectedChannel = ADC_CHANNEL_15;
  sConfigInjected.InjectedRank = 3;
  if (HAL_ADCEx_InjectedConfigChannel(&hadc1, &sConfigInjected) != HAL_OK)
  {
    Error_Handler();
  }

  /** Configure for the selected ADC regular channel its corresponding rank in the sequencer and its sample time.
  */
  sConfig.Channel = ADC_CHANNEL_14;
  sConfig.Rank = 1;
  sConfig.SamplingTime = ADC_SAMPLETIME_56CYCLES;
  sConfig.Offset = 0;

  if (HAL_ADC_ConfigChannel(&hadc1, &sConfig) != HAL_OK)
  {
    Error_Handler();
  }

}

static void MX_ADC2_Init(void)
{

  ADC_InjectionConfTypeDef sConfigInjected = {0};
  ADC_ChannelConfTypeDef sConfig = {0};

  /** Configure the global features of the ADC (Clock, Resolution, Data Alignment and number of conversion)
  */
  hadc2.Instance = ADC2;
  hadc2.Init.ClockPrescaler = ADC_CLOCK_SYNC_PCLK_DIV4;
  hadc2.Init.Resolution = ADC_RESOLUTION_12B;
  hadc2.Init.ScanConvMode = ENABLE;
  hadc2.Init.ContinuousConvMode = DISABLE;
  hadc2.Init.DiscontinuousConvMode = DISABLE;
  hadc2.Init.ExternalTrigConvEdge = ADC_EXTERNALTRIGCONVEDGE_NONE;
  hadc2.Init.ExternalTrigConv = ADC_SOFTWARE_START;
  hadc2.Init.DataAlign = ADC_DATAALIGN_LEFT;
  hadc2.Init.NbrOfConversion = 1;
  hadc2.Init.DMAContinuousRequests = DISABLE;
  hadc2.Init.EOCSelection = ADC_EOC_SINGLE_CONV;
  if (HAL_ADC_Init(&hadc2) != HAL_OK)
  {
    Error_Handler();
  }

  /** Configures for the selected ADC injected channel its corresponding rank in the sequencer and its sample time
  */
  sConfigInjected.InjectedChannel = ADC_CHANNEL_9;
  sConfigInjected.InjectedRank = 1;
  sConfigInjected.InjectedNbrOfConversion = 3;
  sConfigInjected.InjectedSamplingTime = ADC_SAMPLETIME_3CYCLES;
  sConfigInjected.ExternalTrigInjecConvEdge = ADC_EXTERNALTRIGINJECCONVEDGE_RISING;
  sConfigInjected.ExternalTrigInjecConv = ADC_EXTERNALTRIGINJECCONV_T1_CC4;
  sConfigInjected.AutoInjectedConv = DISABLE;
  sConfigInjected.InjectedDiscontinuousConvMode = ENABLE;
  sConfigInjected.InjectedOffset = 0;
  if (HAL_ADCEx_InjectedConfigChannel(&hadc2, &sConfigInjected) != HAL_OK)
  {
    Error_Handler();
  }

  /** Configures for the selected ADC injected channel its corresponding rank in the sequencer and its sample time
  */
  sConfigInjected.InjectedChannel = ADC_CHANNEL_8;
  sConfigInjected.InjectedRank = 2;
  if (HAL_ADCEx_InjectedConfigChannel(&hadc2, &sConfigInjected) != HAL_OK)
  {
    Error_Handler();
  }

  /** Configures for the selected ADC injected channel its corresponding rank in the sequencer and its sample time
  */
  sConfigInjected.InjectedChannel = ADC_CHANNEL_15;
  sConfigInjected.InjectedRank = 3;
  if (HAL_ADCEx_InjectedConfigChannel(&hadc2, &sConfigInjected) != HAL_OK)
  {
    Error_Handler();
  }

  /** Configure for the selected ADC regular channel its corresponding rank in the sequencer and its sample time.
  */
  sConfig.Channel = ADC_CHANNEL_9;
  sConfig.Rank = 1;
  sConfig.SamplingTime = ADC_SAMPLETIME_3CYCLES;
  if (HAL_ADC_ConfigChannel(&hadc2, &sConfig) != HAL_OK)
  {
    Error_Handler();
  }

}

static void MX_TIM1_Init(void)
{

  TIM_SlaveConfigTypeDef sSlaveConfig = {0};
  TIM_MasterConfigTypeDef sMasterConfig = {0};
  TIM_OC_InitTypeDef sConfigOC = {0};
  TIM_BreakDeadTimeConfigTypeDef sBreakDeadTimeConfig = {0};

  htim1.Instance = TIM1;
  htim1.Init.Prescaler = ((TIM_CLOCK_DIVIDER) - 1);
  htim1.Init.CounterMode = TIM_COUNTERMODE_CENTERALIGNED1;
  htim1.Init.Period = ((PWM_PERIOD_CYCLES) / 2);
  htim1.Init.ClockDivision = TIM_CLOCKDIVISION_DIV2;
  htim1.Init.RepetitionCounter = (REP_COUNTER);
  htim1.Init.AutoReloadPreload = TIM_AUTORELOAD_PRELOAD_DISABLE;
  if (HAL_TIM_Base_Init(&htim1) != HAL_OK)
  {
    Error_Handler();
  }
  if (HAL_TIM_PWM_Init(&htim1) != HAL_OK)
  {
    Error_Handler();
  }
  sSlaveConfig.SlaveMode = TIM_SLAVEMODE_TRIGGER;
  sSlaveConfig.InputTrigger = TIM_TS_ITR1;
  if (HAL_TIM_SlaveConfigSynchro(&htim1, &sSlaveConfig) != HAL_OK)
  {
    Error_Handler();
  }
  sMasterConfig.MasterOutputTrigger = TIM_TRGO_RESET;
  sMasterConfig.MasterSlaveMode = TIM_MASTERSLAVEMODE_DISABLE;
  if (HAL_TIMEx_MasterConfigSynchronization(&htim1, &sMasterConfig) != HAL_OK)
  {
    Error_Handler();
  }
  sConfigOC.OCMode = TIM_OCMODE_PWM1;
  sConfigOC.Pulse = 0;
  sConfigOC.OCPolarity = TIM_OCPOLARITY_HIGH;
  sConfigOC.OCNPolarity = TIM_OCNPOLARITY_HIGH;
  sConfigOC.OCFastMode = TIM_OCFAST_DISABLE;
  sConfigOC.OCIdleState = TIM_OCIDLESTATE_RESET;
  sConfigOC.OCNIdleState = TIM_OCNIDLESTATE_RESET;
  if (HAL_TIM_PWM_ConfigChannel(&htim1, &sConfigOC, TIM_CHANNEL_1) != HAL_OK)
  {
    Error_Handler();
  }
  if (HAL_TIM_PWM_ConfigChannel(&htim1, &sConfigOC, TIM_CHANNEL_2) != HAL_OK)
  {
    Error_Handler();
  }
  if (HAL_TIM_PWM_ConfigChannel(&htim1, &sConfigOC, TIM_CHANNEL_3) != HAL_OK)
  {
    Error_Handler();
  }
  sConfigOC.OCMode = TIM_OCMODE_PWM2;
  sConfigOC.Pulse = (((PWM_PERIOD_CYCLES) / 2) - (HTMIN));
  if (HAL_TIM_PWM_ConfigChannel(&htim1, &sConfigOC, TIM_CHANNEL_4) != HAL_OK)
  {
    Error_Handler();
  }
  sBreakDeadTimeConfig.OffStateRunMode = TIM_OSSR_ENABLE;
  sBreakDeadTimeConfig.OffStateIDLEMode = TIM_OSSI_ENABLE;
  sBreakDeadTimeConfig.LockLevel = TIM_LOCKLEVEL_1;
  sBreakDeadTimeConfig.DeadTime = ((DEAD_TIME_COUNTS) / 2);
  sBreakDeadTimeConfig.BreakState = TIM_BREAK_DISABLE;
  sBreakDeadTimeConfig.BreakPolarity = TIM_BREAKPOLARITY_LOW;
  sBreakDeadTimeConfig.AutomaticOutput = TIM_AUTOMATICOUTPUT_DISABLE;
  if (HAL_TIMEx_ConfigBreakDeadTime(&htim1, &sBreakDeadTimeConfig) != HAL_OK)
  {
    Error_Handler();
  }
  HAL_TIM_MspPostInit(&htim1);

}

static void MX_USART6_UART_Init(void)
{

  huart6.Instance = USART6;
  huart6.Init.BaudRate = 115200;
  huart6.Init.WordLength = UART_WORDLENGTH_8B;
  huart6.Init.StopBits = UART_STOPBITS_1;
  huart6.Init.Parity = UART_PARITY_NONE;
  huart6.Init.Mode = UART_MODE_TX_RX;
  huart6.Init.HwFlowCtl = UART_HWCONTROL_NONE;
  huart6.Init.OverSampling = UART_OVERSAMPLING_16;
  if (HAL_UART_Init(&huart6) != HAL_OK)
  {
    Error_Handler();
  }

}

static void MX_GPIO_Init(void)
{
  GPIO_InitTypeDef GPIO_InitStruct = {0};

  /* GPIO Ports Clock Enable */
  __HAL_RCC_GPIOE_CLK_ENABLE();
  __HAL_RCC_GPIOH_CLK_ENABLE();
  __HAL_RCC_GPIOC_CLK_ENABLE();
  __HAL_RCC_GPIOB_CLK_ENABLE();

  /*Configure GPIO pin : Start_Stop_Pin */
  GPIO_InitStruct.Pin = Start_Stop_Pin;
  GPIO_InitStruct.Mode = GPIO_MODE_IT_FALLING;
  GPIO_InitStruct.Pull = GPIO_PULLUP;
  HAL_GPIO_Init(Start_Stop_GPIO_Port, &GPIO_InitStruct);

}

void Error_Handler(void)
{
}
